AUTOSAR XML (schema 00044)
package /ComponentTypes
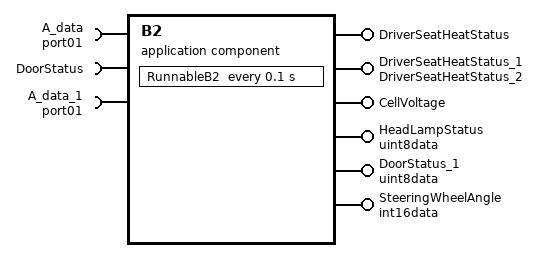
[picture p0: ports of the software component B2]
  application sw component type B2
    require port A_data: required-com-specs=[{data-element=Element1, init-value=0}, {data-element=Element2, init-value=0}], required-interface=port01
    provide port DriverSeatHeatStatus: nonqueued-sender-com-spec{data-element=DriverSeatHeatStatus, init-value=0}, provided-interface=DriverSeatHeatStatus
    require port DoorStatus: nonqueued-receiver-com-spec{data-element=data, filter=data-filter-type=ALWAYS}, required-interface=DoorStatus
    provide port DriverSeatHeatStatus_1: nonqueued-sender-com-spec{data-element=DriverSeatHeatStatus, init-value=0}, provided-interface=DriverSeatHeatStatus_2
    provide port CellVoltage: provided-interface=CellVoltage
      provided-com-specs:
        data-element=CellVoltage{01..16}, init-value=0
    require port A_data_1: required-interface=port01
      required-com-specs:
        data-element=Element1, filter=data-filter-type=ALWAYS, init-value=0
        data-element=Element2, filter=data-filter-type=ALWAYS, init-value=0
    provide port HeadLampStatus: nonqueued-sender-com-spec{data-element=data, init-value=0}, provided-interface=uint8data
    provide port DoorStatus_1: nonqueued-sender-com-spec{data-element=data, init-value=0}, provided-interface=uint8data
    provide port SteeringWheelAngle: nonqueued-sender-com-spec{data-element=Element, init-value=0}, provided-interface=int16data
    behavior B2_InternalBehavior: supports-multiple-instantiation=true
      timing event TMT_RunnableB: start-on-event=RunnableB2, period=0.1
      runnable RunnableB2
        data-receive-point-by-arguments:
          5 x access:
            REC_port01_Element: accessed-variable=A_data.Element1
            REC_port01_Element_1: accessed-variable=A_data.Element2
            REC_A_data_1_Element1: accessed-variable=A_data_1.Element1
            REC_A_data_1_Element2: accessed-variable=A_data_1.Element2
            REC_DoorStatus_data: accessed-variable=DoorStatus.data
        data-send-points:
          21 x access:
            SEND_CellVoltage_CellVoltage{01..16}: accessed-variable=CellVoltage.CellVoltage{01..16}
            SEND_DoorStatus_1_data: accessed-variable=DoorStatus_1.data
            SEND_DriverSeatHeatStatus_DriverSeatHeatStatus: accessed-variable=DriverSeatHeatStatus.DriverSeatHeatStatus
            SEND_DriverSeatHeatStatus_1_DriverSeatHeatStatus: accessed-variable=DriverSeatHeatStatus_1.DriverSeatHeatStatus
            SEND_HeadLampStatus_data: accessed-variable=HeadLampStatus.data
            SEND_SteeringWheelAngle_Element: accessed-variable=SteeringWheelAngle.Element
  swc implementation B2_Implementation: behavior=B2_InternalBehavior
